# ATSAM3SD8B register map
Vendor: Atmel; Series: SAM3SD8; File version: 0
CPU: CM3 r2p0, selectable endian, MPU, no FPU, 4 interrupt priority bits
Registers are 32-bit, read-write, reset 0x0 unless marked. A register's access mark holds for its fields unless they carry their own. Offsets are from the block's base; [hi:lo] are bit positions; {n}, {i} and the like mark numbered series; 'fields as' and 'values as' point back to an identical list.

## MPU — Memory Protection Unit (MPU)
Base 0x4000D000; register names take the prefix MPU_
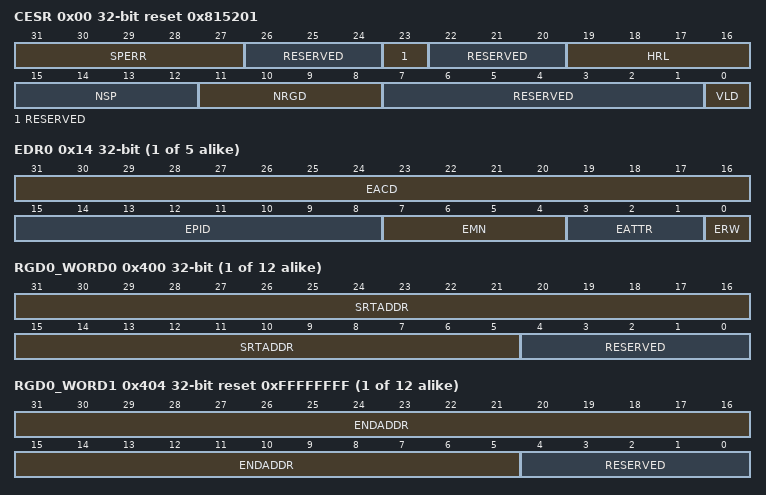
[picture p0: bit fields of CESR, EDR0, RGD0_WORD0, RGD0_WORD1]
0x00 CESR access per field reset 0x815201 — Control/Error Status Register
  [31:27] SPERR rw — Slave port n error
    0=No error has occurred for slave port n; 1=An error has occurred for slave port n
  [26:24] RESERVED ro
  [23] RESERVED ro
  [22:20] RESERVED ro
  [19:16] HRL ro — Hardware revision level
  [15:12] NSP ro — Number of slave ports
  [11:8] NRGD ro — Number of region descriptors
    0=8 region descriptors; 1=12 region descriptors; 2=16 region descriptors
  [7:1] RESERVED ro
  [0] VLD rw — Valid (global enable/disable for the MPU)
    0=MPU is disabled. All accesses from all bus masters are allowed.; 1=MPU is enabled
{0x10+8i} EAR{i} (i=0..4) ro reset not defined — Error Address Register, Slave Port n
  [31:0] EADDR — Error address
{0x14+8i} EDR{i} (i=0..4) ro reset not defined — Error Detail Register, Slave Port n
  [31:16] EACD — Error access control detail
  [15:8] EPID — Error process identification
  [7:4] EMN — Error master number
  [3:1] EATTR — Error attributes
    0=User mode, instruction access; 1=User mode, data access; 2=Supervisor mode, instruction access; 3=Supervisor mode, data access
  [0] ERW — Error read/write
    0=Read; 1=Write
{0x400+0x10*i} RGD{i}_WORD0 (i=0..11) access per field — Region Descriptor n, Word 0
  [31:5] SRTADDR rw — Start address
  [4:0] RESERVED ro
{0x404+0x10*i} RGD{i}_WORD1 (i=0..11) access per field reset 0xFFFFFFFF — Region Descriptor n, Word 1
  [31:5] ENDADDR rw — End address
  [4:0] RESERVED ro
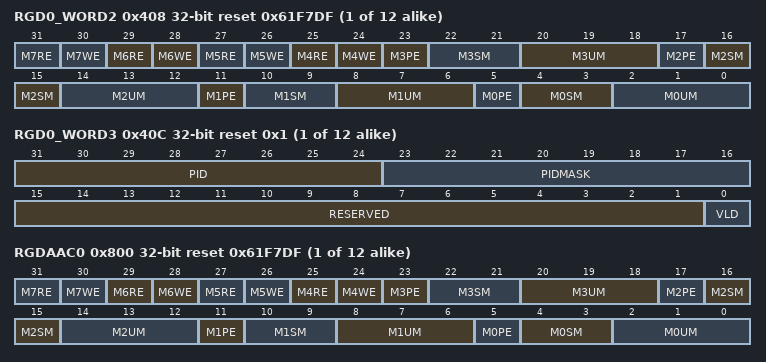
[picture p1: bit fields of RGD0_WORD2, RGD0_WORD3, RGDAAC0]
{0x408+0x10*i} RGD{i}_WORD2 (i=0..11) reset 0x61F7DF — Region Descriptor n, Word 2
  [2n+17] M{n}RE (n=4..7) — Bus master {n} read enable.
    0=Bus master {n} reads terminate with an access error and the read is not performed; 1=Bus master {n} reads allowed
  [2n+16] M{n}WE (n=4..7) — Bus master {n} write enable
    0=Bus master {n} writes terminate with an access error and the write is not performed; 1=Bus master {n} writes allowed
  [23] M3PE — Bus master 3 process identifier enable.
    0=Do not include the process identifier in the evaluation; 1=Include the process identifier and mask (RGDn_WORD3) in the region hit evaluation
  [22:21] M3SM — Bus master 3 supervisor mode access control
    0=r/w/x; read, write and execute allowed; 1=r/x; read and execute allowed, but no write; 2=r/w; read and write allowed, but no execute; 3=Same as user mode defined in M3UM
  [20:18] M3UM — Bus master 3 user mode access control
    0=An attempted access of that mode may be terminated with an access error (if not allowed by another descriptor) and the access not performed; 1=Allows the given access type to occur
  [17] M2PE — Bus master 2 process identifier enable
  [16:15] M2SM — Bus master 2 supervisor mode access control
  [14:12] M2UM — Bus master 2 user mode access control
  [11] M1PE — Bus master 1 process identifier enable
  [10:9] M1SM — Bus master 1 supervisor mode access control
  [8:6] M1UM — Bus master 1 user mode access control
  [5] M0PE — Bus master 0 process identifier enable
  [4:3] M0SM — Bus master 0 supervisor mode access control
  [2:0] M0UM — Bus master 0 user mode access control
{0x40C+0x10*i} RGD{i}_WORD3 (i=0..11) access per field reset 0x1 — Region Descriptor n, Word 3
  [31:24] PID rw — Process identifier
  [23:16] PIDMASK rw — Process identifier mask
  [15:1] RESERVED ro
  [0] VLD rw — Valid
    0=Region descriptor is invalid; 1=Region descriptor is valid
{0x800+4i} RGDAAC{i} (i=0..11) reset 0x61F7DF — Region Descriptor Alternate Access Control n
  [2n+17] M{n}RE (n=4..7) — Bus master {n} read enable.
    values as RGD0_WORD2.M4RE
  [2n+16] M{n}WE (n=4..7) — Bus master {n} write enable
    values as RGD0_WORD2.M4WE
  [23] M3PE — Bus master 3 process identifier enable.
    0=Do not include the process identifier in the evaluation; 1=Include the process identifier and mask (RGDn.RGDAAC) in the region hit evaluation
  [22:21] M3SM — Bus master 3 supervisor mode access control
    values as RGD0_WORD2.M3SM
  [20:18] M3UM — Bus master 3 user mode access control
    values as RGD0_WORD2.M3UM
  [17] M2PE — Bus master 2 process identifier enable
  [16:15] M2SM — Bus master 2 supervisor mode access control
  [14:12] M2UM — Bus master 2 user mode access control
  [11] M1PE — Bus master 1 process identifier enable
  [10:9] M1SM — Bus master 1 supervisor mode access control
  [8:6] M1UM — Bus master 1 user mode access control
  [5] M0PE — Bus master 0 process identifier enable
  [4:3] M0SM — Bus master 0 supervisor mode access control
  [2:0] M0UM — Bus master 0 user mode access control
